AUTOSAR XML (schema 4-0-3)
standard types defined: UInt32, UInt8
package /AUTOSAR_Platform/DataConstrs
  range DC_UInt8: raw 0..255
package /PATAC/MSM/ComponentTypes
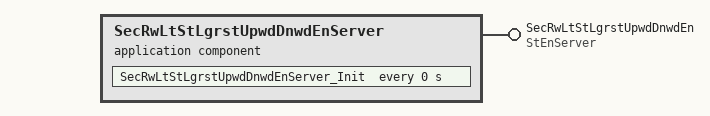
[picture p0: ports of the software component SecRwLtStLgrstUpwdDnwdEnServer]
  application sw component type SecRwLtStLgrstUpwdDnwdEnServer
    provide port SecRwLtStLgrstUpwdDnwdEn: provided-com-specs=[{operation=Clear, queue-length=1}, {operation=Get, queue-length=1}, {operation=Set, queue-length=1}], provided-interface=StEnServer
    behavior SecRwLtStLgrstUpwdDnwdEnServer_InternalBehavior
      operation invoked event OIT_SecRwLtStLgrstUpwdDnwdEn_Clear_SecRwLtStLgrstUpwdDnwdEn_Clear: start-on-event=SecRwLtStLgrstUpwdDnwdEn_Clear, operation=SecRwLtStLgrstUpwdDnwdEn.Clear
      operation invoked event OIT_SecRwLtStLgrstUpwdDnwdEn_Get_SecRwLtStLgrstUpwdDnwdEn_Get: start-on-event=SecRwLtStLgrstUpwdDnwdEn_Get, operation=SecRwLtStLgrstUpwdDnwdEn.Get
      operation invoked event OIT_SecRwLtStLgrstUpwdDnwdEn_Set_SecRwLtStLgrstUpwdDnwdEn_Set: start-on-event=SecRwLtStLgrstUpwdDnwdEn_Set, operation=SecRwLtStLgrstUpwdDnwdEn.Set
      timing event SecRwLtStLgrstUpwdDnwdEnServer_InitEvent: start-on-event=SecRwLtStLgrstUpwdDnwdEnServer_Init, period=0
      4 x runnable:
        SecRwLtStLgrstUpwdDnwdEn_Clear
        SecRwLtStLgrstUpwdDnwdEn_Get
        SecRwLtStLgrstUpwdDnwdEn_Set
        SecRwLtStLgrstUpwdDnwdEnServer_Init
  swc implementation SecRwLtStLgrstUpwdDnwdEnServer_Implementation: behavior=SecRwLtStLgrstUpwdDnwdEnServer_InternalBehavior
    code-descriptors:
      code Default: artifact-descriptors=autosar-engineering-object={short-label=Default, category=SWSRC}
package /PATAC/MSM/ModeAdjust/PortInterface
  client server interface StEnServer
    operation Clear
      arg data: type=UInt8, direction=IN, server-argument-impl-policy=USE-ARGUMENT-TYPE
    operation Get
      arg data: type=UInt32, direction=OUT, server-argument-impl-policy=USE-ARGUMENT-TYPE
    operation Set
      arg data: type=UInt8, direction=IN, server-argument-impl-policy=USE-ARGUMENT-TYPE
